VERSION "TE CAN(6) Work x0400000000019499"

NS_ :

BS_:

BU_: BCM CSM DSM_Master DSM_Slave1 Fleet_tracker Tester

BO_ 2364565297 CRNTGEAR: 8 BCM
 SG_ CrntGearEngdSts : 0|2@1+ (1,0) [0|1] "" CSM,DSM_Master,DSM_Slave1

BO_ 2364564771 DBLLCKSNSR: 8 CSM
 SG_ DblLckSnsrRprtdSts : 0|3@1+ (0,0) [0|5] "" BCM

BO_ 2364565809 DBLLCKSNSRTRCK: 8 BCM
 SG_ DblLckSnsrStsTrck : 0|3@1+ (1,0) [0|5] "" DSM_Master

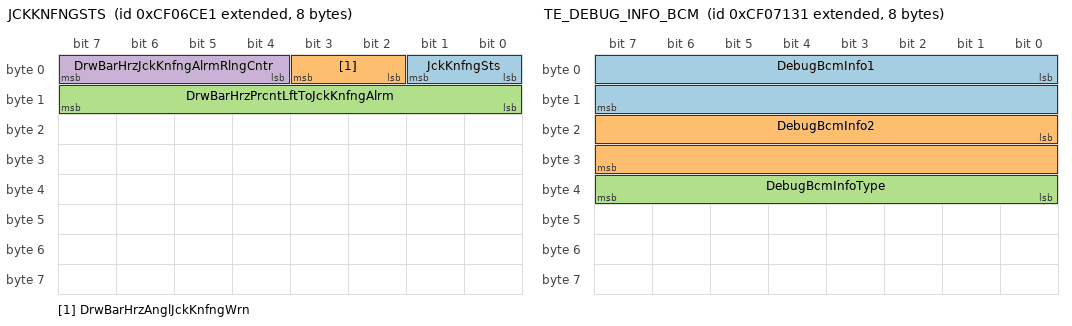
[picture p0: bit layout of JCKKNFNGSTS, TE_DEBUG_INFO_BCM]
BO_ 2364566753 JCKKNFNGSTS: 8 DSM_Master
 SG_ JckKnfngSts : 0|2@1+ (1,0) [0|1] "" BCM
 SG_ DrwBarHrzAnglJckKnfngWrn : 2|2@1+ (1,0) [0|1] "" BCM
 SG_ DrwBarHrzPrcntLftToJckKnfngAlrm : 8|8@1+ (1,0) [0|100] "Percent" BCM
 SG_ DrwBarHrzJckKnfngAlrmRlngCntr : 4|4@1+ (1,0) [0|15] "" BCM

BO_ 2364566321 VEHICLEINFO: 8 BCM
 SG_ KL15Sts : 0|2@1+ (1,0) [0|0] "" CSM,DSM_Master

BO_ 2016 BCMDIAGPHYSRVCREQ: 8 Tester
 SG_ bcmdiagrxsignal : 0|64@1+ (1,0) [0|4] "" BCM

BO_ 2024 BCMDIAGSRVCRSP: 8 BCM

BO_ 2018 DSMMDIAGPHYSRVCREQ: 8 Tester
 SG_ dsmdiagrxsignal : 0|64@1+ (1,0) [0|4] "" DSM_Master,DSM_Slave1

BO_ 2026 DSMMDIAGRVCRSP: 8 DSM_Master

BO_ 2019 DSMSDIAGPHYSRVCREQ: 8 Tester

BO_ 2027 DSMSDIAGSRVCRSP: 8 DSM_Slave1

BO_ 2017 CSMDIAGPHYSRVCREQ: 8 Tester
 SG_ csmdiagrxsignal : 0|64@1+ (1,0) [0|4] "" CSM

BO_ 2025 CSMDIAGSRVCRSP: 8 CSM

BO_ 2047 DIAGFNKSRVCREQ: 8 Tester
 SG_ diagfunctionalsignal : 0|64@1+ (1,0) [0|4] "" BCM,CSM,DSM_Master,DSM_Slave1

BO_ 224 TesterPresentPhys: 8 Tester

BO_ 232 TesterPresentFunc: 8 Tester

BO_ 2364567526 TE_DEBUG_BCM: 8 Tester
 SG_ DebugBcmCmd : 0|8@1+ (1,0) [0|0] "" BCM
 SG_ DebugBcmValue : 16|16@1+ (1,0) [0|0] "" BCM

BO_ 2364567782 TE_DEBUG_CSM: 8 Tester
 SG_ DebugCsmCmd : 0|8@1+ (1,0) [0|0] "" CSM
 SG_ DebugCsmValue : 16|16@1+ (1,0) [0|0] "" CSM

BO_ 2364567857 TE_DEBUG_INFO_BCM: 8 BCM
 SG_ DebugBcmInfo1 : 0|16@1+ (1,0) [0|65535] "" Tester
 SG_ DebugBcmInfo2 : 16|16@1+ (1,0) [0|65535] "" Tester
 SG_ DebugBcmInfoType : 32|8@1+ (1,0) [0|15] "" Tester

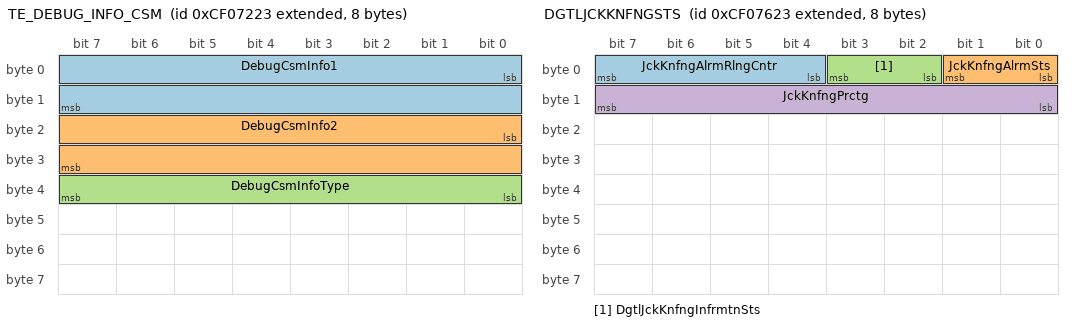
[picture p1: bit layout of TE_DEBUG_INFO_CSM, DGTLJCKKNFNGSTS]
BO_ 2364568099 TE_DEBUG_INFO_CSM: 8 CSM
 SG_ DebugCsmInfo1 : 0|16@1+ (1,0) [0|65535] "" Tester
 SG_ DebugCsmInfo2 : 16|16@1+ (1,0) [0|65535] "" Tester
 SG_ DebugCsmInfoType : 32|8@1+ (1,0) [0|15] "" Tester

BO_ 2364568547 TM_AND_DAT_SETPNT: 8 Fleet_tracker
 SG_ CrntTmAndDateSetPnt : 0|64@1+ (1,0) [0|0] "ms" BCM

BO_ 2364569123 DGTLJCKKNFNGSTS: 8 CSM
 SG_ JckKnfngAlrmRlngCntr : 4|4@1+ (1,0) [0|15] "" BCM
 SG_ JckKnfngAlrmSts : 0|2@1+ (1,0) [0|1] "" BCM
 SG_ DgtlJckKnfngInfrmtnSts : 2|2@1+ (1,0) [0|1] "" BCM
 SG_ JckKnfngPrctg : 8|8@1+ (1,0) [0|100] "Percent" BCM

BO_ 2364568867 CSMSRVCINDREQ: 8 CSM
 SG_ CsmSrvcIndReq : 0|64@1+ (1,0) [0|0] "" BCM

BO_ 2364568801 DSMSRVCINDREQ: 8 DSM_Master
 SG_ DsmSrvcIndReq : 0|64@1+ (1,0) [0|0] "" BCM

BO_ 2364569393 CRNTTMANDDATE: 8 BCM
 SG_ CrntTmAndDate : 0|64@1+ (1,0) [0|1] "ms" CSM,DSM_Master,DSM_Slave1,Fleet_tracker

CM_ "TE CAN";
CM_ BO_ 2364565297 "PGN 61543 Current Gear";
CM_ SG_ 2364565297 CrntGearEngdSts "<Enter a description>";
CM_ BO_ 2364564771 "PGN 61541 Double lock sensor";
CM_ BO_ 2364565809 "PGN 61545 Double lock sensor at truck";
CM_ BO_ 2364566753 "PGN 61548 Jack knifing status";
CM_ SG_ 2364566753 DrwBarHrzJckKnfngAlrmRlngCntr "<Enter a description>";
CM_ BO_ 2364566321 "PGN 61547 Vehicle info";
CM_ BO_ 2016 "BCM diagnostic physical service request";
CM_ SG_ 2016 bcmdiagrxsignal "<Enter a description>";
CM_ BO_ 2024 "BCM Diagnostic physical service response";
CM_ BO_ 2018 "DSM diagnostic physical service request";
CM_ SG_ 2018 dsmdiagrxsignal "<Enter a description>";
CM_ BO_ 2026 "DSM Diagnostic physical service response";
CM_ BO_ 2019 "DSM diagnostic physical service request";
CM_ BO_ 2027 "DSM Diagnostic physical service response";
CM_ BO_ 2017 "CSM diagnostic physical service request";
CM_ SG_ 2017 csmdiagrxsignal "<Enter a description>";
CM_ BO_ 2025 "CSM Diagnose Physical Service Response";
CM_ BO_ 2047 "Diagnostic functional service request";
CM_ SG_ 2047 diagfunctionalsignal "<Enter a description>";
CM_ BO_ 224 "Defines the TesterPresent message for physically addressed requests used to keep a diagnostic session active.";
CM_ BO_ 232 "Defines the TesterPresent message for functionally addressed requests used to keep a diagnostic session active.";
CM_ BO_ 2364567526 "PGN 61551 Debugger request BSM";
CM_ SG_ 2364567526 DebugBcmCmd "<Enter a description>";
CM_ SG_ 2364567526 DebugBcmValue "<Enter a description>";
CM_ BO_ 2364567782 "PGN 61552 Debugger request CSM";
CM_ SG_ 2364567782 DebugCsmCmd "<Enter a description>";
CM_ SG_ 2364567782 DebugCsmValue "<Enter a description>";
CM_ BO_ 2364567857 "PGN 61553 Debugger resoponse BCM";
CM_ SG_ 2364567857 DebugBcmInfo1 "<Enter a description>";
CM_ SG_ 2364567857 DebugBcmInfo2 "<Enter a description>";
CM_ SG_ 2364567857 DebugBcmInfoType "<Enter a description>";
CM_ BO_ 2364568099 "PGN 61554 Debugger resoponse CSM";
CM_ SG_ 2364568099 DebugCsmInfo1 "<Enter a description>";
CM_ SG_ 2364568099 DebugCsmInfo2 "<Enter a description>";
CM_ SG_ 2364568099 DebugCsmInfoType "<Enter a description>";
CM_ BO_ 2364568547 "PGN 61555 Time and date setpoint from GPS. Epoch 1/1 1970";
CM_ SG_ 2364568547 CrntTmAndDateSetPnt "<Enter a description>";
CM_ BO_ 2364569123 "PGN 61555 Digital Jack knifing status";
CM_ SG_ 2364569123 JckKnfngAlrmRlngCntr "<Enter a description>";
CM_ SG_ 2364569123 JckKnfngAlrmSts "<Enter a description>";
CM_ SG_ 2364569123 DgtlJckKnfngInfrmtnSts "<Enter a description>";
CM_ SG_ 2364569123 JckKnfngPrctg "<Enter a description>";
CM_ BO_ 2364568867 "PGN 61557 CSM Service indication request";
CM_ SG_ 2364568867 CsmSrvcIndReq "<Enter a description>";
CM_ BO_ 2364568801 "PGN 61556 DSM service indication request";
CM_ SG_ 2364568801 DsmSrvcIndReq "<Enter a description>";
CM_ BO_ 2364569393 "PGN 61559 Current time and date";
CM_ SG_ 2364569393 CrntTmAndDate "<Enter a description>";

BA_DEF_  "DatabaseVersion" STRING ;
BA_DEF_  "ProtocolType" STRING ;
BA_DEF_  "SAE_J1939_21_SpecVersion" STRING ;
BA_DEF_  "SAE_J1939_71_SpecVersion" STRING ;
BA_DEF_  "SAE_J1939_73_SpecVersion" STRING ;
BA_DEF_  "Manufacturer" STRING ;
BA_DEF_  "BusType" STRING ;
BA_DEF_ BU_  "ECU" STRING ;
BA_DEF_ BU_  "NmJ1939AAC" INT 0 1;
BA_DEF_ BU_  "NmJ1939IndustryGroup" INT 0 7;
BA_DEF_ BU_  "NmJ1939System" INT 0 127;
BA_DEF_ BU_  "NmJ1939SystemInstance" INT 0 15;
BA_DEF_ BU_  "NmJ1939ECUInstance" INT 0 3;
BA_DEF_ BU_  "NmJ1939Function" INT 0 255;
BA_DEF_ BU_  "NmJ1939FunctionInstance" INT 0 7;
BA_DEF_ BU_  "NmJ1939ManufacturerCode" INT 0 2047;
BA_DEF_ BU_  "NmJ1939IdentityNumber" INT 0 2097151;
BA_DEF_ BU_  "NmStationAddress" INT 0 255;
BA_DEF_ BU_  "NodeLayerModules" STRING ;
BA_DEF_ BO_  "SingleFrame" INT 0 1;
BA_DEF_ BO_  "GenMsgStartDelayTime" INT 0 10000;
BA_DEF_ BO_  "GenMsgDelayTime" INT 0 10000;
BA_DEF_ BO_  "GenMsgILSupport" ENUM  "Yes","No";
BA_DEF_ BO_  "SAE_Document" STRING ;
BA_DEF_ BO_  "GenMsgRequestable" INT 0 1;
BA_DEF_ BO_  "GenMsgSendType" ENUM  "cyclic","spontan","cyclicIfActive","spontanWithDelay","cyclicAndSpontan","cyclicAndSpontanWithDelay","spontanWithRepitition","cyclicIfActiveAndSpontanWD","noMsgSendType";
BA_DEF_ BO_  "VFrameFormat" ENUM  "StandardCAN","ExtendedCAN","reserved","J1939PG";
BA_DEF_ BO_  "GenMsgCycleTime" INT 0 3600000;
BA_DEF_ BO_  "GenMsgNrOfRepetition" INT 0 1000;
BA_DEF_ SG_  "SignalStartPosition" INT 0 63;
BA_DEF_ SG_  "GenSigStartValue" FLOAT 0 10000;
BA_DEF_ SG_  "GenSigSendType" ENUM  "Cyclic","OnWrite","OnWriteWithRepetition","OnChange","OnChangeWithRepetition","IfActive","IfActiveWithRepetition","NoSigSendType";
BA_DEF_ SG_  "GenSigILSupport" ENUM  "Yes","No";
BA_DEF_ SG_  "SPN" INT 0 524287;
BA_DEF_ SG_  "SigType" ENUM  "Default","Range","RangeSigned","ASCII","Discrete","Control","ReferencePGN","DTC","StringDelimiter","StringLength","StringLengthControl";

BA_DEF_DEF_  "DatabaseVersion" "";
BA_DEF_DEF_  "ProtocolType" "-";
BA_DEF_DEF_  "SAE_J1939_21_SpecVersion" "";
BA_DEF_DEF_  "SAE_J1939_71_SpecVersion" "";
BA_DEF_DEF_  "SAE_J1939_73_SpecVersion" "";
BA_DEF_DEF_  "Manufacturer" "VBG Truck Equipment";
BA_DEF_DEF_  "BusType" "CAN";
BA_DEF_DEF_  "ECU" "";
BA_DEF_DEF_  "NmJ1939AAC" 0;
BA_DEF_DEF_  "NmJ1939IndustryGroup" 1;
BA_DEF_DEF_  "NmJ1939System" 0;
BA_DEF_DEF_  "NmJ1939SystemInstance" 0;
BA_DEF_DEF_  "NmJ1939ECUInstance" 0;
BA_DEF_DEF_  "NmJ1939Function" 0;
BA_DEF_DEF_  "NmJ1939FunctionInstance" 0;
BA_DEF_DEF_  "NmJ1939ManufacturerCode" 0;
BA_DEF_DEF_  "NmJ1939IdentityNumber" 0;
BA_DEF_DEF_  "NmStationAddress" 0;
BA_DEF_DEF_  "NodeLayerModules" "CANoeILNLVector.dll";
BA_DEF_DEF_  "SingleFrame" 1;
BA_DEF_DEF_  "GenMsgStartDelayTime" 0;
BA_DEF_DEF_  "GenMsgDelayTime" 0;
BA_DEF_DEF_  "GenMsgILSupport" "Yes";
BA_DEF_DEF_  "SAE_Document" "";
BA_DEF_DEF_  "GenMsgRequestable" ;
BA_DEF_DEF_  "GenMsgSendType" "NoMsgSendType";
BA_DEF_DEF_  "VFrameFormat" "J1939PG";
BA_DEF_DEF_  "GenMsgCycleTime" ;
BA_DEF_DEF_  "GenMsgNrOfRepetition" 1;
BA_DEF_DEF_  "SignalStartPosition" 0;
BA_DEF_DEF_  "GenSigStartValue" 0;
BA_DEF_DEF_  "GenSigSendType" "NoSigSendType";
BA_DEF_DEF_  "GenSigILSupport" "Yes";
BA_DEF_DEF_  "SPN" 0;
BA_DEF_DEF_  "SigType" "-";
BA_ "ProtocolType" "J1939";
BA_ "DatabaseVersion" "1.0";
BA_ "SAE_J1939_21_SpecVersion" "201603";
BA_ "SAE_J1939_71_SpecVersion" "201610";
BA_ "SAE_J1939_73_SpecVersion" "201705";
BA_ "ECU" BU_ BCM "BCM";
BA_ "NmJ1939Function" BU_ BCM 255;
BA_ "NmJ1939ManufacturerCode" BU_ BCM 925;
BA_ "NmJ1939IdentityNumber" BU_ BCM 1048575;
BA_ "NmStationAddress" BU_ BCM 49;
BA_ "ECU" BU_ CSM "CSM";
BA_ "NmJ1939Function" BU_ CSM 255;
BA_ "NmJ1939ManufacturerCode" BU_ CSM 926;
BA_ "NmJ1939IdentityNumber" BU_ CSM 1048574;
BA_ "NmStationAddress" BU_ CSM 35;
BA_ "ECU" BU_ DSM_Master "DSM";
BA_ "NmJ1939Function" BU_ DSM_Master 255;
BA_ "NmJ1939ManufacturerCode" BU_ DSM_Master 926;
BA_ "NmJ1939IdentityNumber" BU_ DSM_Master 1048573;
BA_ "NmStationAddress" BU_ DSM_Master 225;
BA_ "NmStationAddress" BU_ DSM_Slave1 226;
BA_ "ECU" BU_ DSM_Slave1 "DSM";
BA_ "NmJ1939Function" BU_ DSM_Slave1 255;
BA_ "NmJ1939IdentityNumber" BU_ DSM_Slave1 1048573;
BA_ "NmJ1939ManufacturerCode" BU_ DSM_Slave1 926;
BA_ "ECU" BU_ Fleet_tracker "IOT";
BA_ "NmJ1939Function" BU_ Fleet_tracker 255;
BA_ "NmJ1939ManufacturerCode" BU_ Fleet_tracker 927;
BA_ "NmJ1939IdentityNumber" BU_ Fleet_tracker 1048572;
BA_ "NmStationAddress" BU_ Fleet_tracker 227;
BA_ "ECU" BU_ Tester "Service tool";
BA_ "NmStationAddress" BU_ Tester 230;
BA_ "NmJ1939Function" BU_ Tester 255;
BA_ "NmJ1939IdentityNumber" BU_ Tester 1048576;
BA_ "NmJ1939ManufacturerCode" BU_ Tester 930;
BA_ "SingleFrame" BO_ 2364565297 0;
BA_ "GenMsgCycleTime" BO_ 2364565297 100;
BA_ "GenMsgSendType" BO_ 2364565297 0;
BA_ "SAE_Document" BO_ 2364565297 "??";
BA_ "GenMsgRequestable" BO_ 2364565297 0;
BA_ "SingleFrame" BO_ 2364564771 0;
BA_ "GenMsgCycleTime" BO_ 2364564771 100;
BA_ "GenMsgSendType" BO_ 2364564771 0;
BA_ "GenSigSendType" SG_ 2364564771 DblLckSnsrRprtdSts 0;
BA_ "SingleFrame" BO_ 2364565809 0;
BA_ "GenMsgCycleTime" BO_ 2364565809 100;
BA_ "GenMsgSendType" BO_ 2364565809 0;
BA_ "GenSigSendType" SG_ 2364565809 DblLckSnsrStsTrck 0;
BA_ "SingleFrame" BO_ 2364566753 0;
BA_ "GenMsgCycleTime" BO_ 2364566753 100;
BA_ "GenMsgSendType" BO_ 2364566753 0;
BA_ "GenSigSendType" SG_ 2364566753 JckKnfngSts 0;
BA_ "GenSigSendType" SG_ 2364566753 DrwBarHrzAnglJckKnfngWrn 0;
BA_ "GenSigSendType" SG_ 2364566753 DrwBarHrzPrcntLftToJckKnfngAlrm 0;
BA_ "GenSigSendType" SG_ 2364566753 DrwBarHrzJckKnfngAlrmRlngCntr 0;
BA_ "SingleFrame" BO_ 2364566321 0;
BA_ "GenMsgCycleTime" BO_ 2364566321 100;
BA_ "GenMsgSendType" BO_ 2364566321 0;
BA_ "GenSigSendType" SG_ 2364566321 KL15Sts 0;
BA_ "SingleFrame" BO_ 2016 0;
BA_ "VFrameFormat" BO_ 2016 0;
BA_ "GenMsgSendType" BO_ 2016 8;
BA_ "SingleFrame" BO_ 2024 0;
BA_ "VFrameFormat" BO_ 2024 0;
BA_ "GenMsgSendType" BO_ 2024 8;
BA_ "SingleFrame" BO_ 2018 0;
BA_ "VFrameFormat" BO_ 2018 0;
BA_ "GenMsgSendType" BO_ 2018 8;
BA_ "SingleFrame" BO_ 2026 0;
BA_ "VFrameFormat" BO_ 2026 0;
BA_ "GenMsgSendType" BO_ 2026 8;
BA_ "SingleFrame" BO_ 2019 0;
BA_ "VFrameFormat" BO_ 2019 0;
BA_ "GenMsgSendType" BO_ 2019 8;
BA_ "SingleFrame" BO_ 2027 0;
BA_ "VFrameFormat" BO_ 2027 0;
BA_ "GenMsgSendType" BO_ 2027 8;
BA_ "SingleFrame" BO_ 2017 0;
BA_ "VFrameFormat" BO_ 2017 0;
BA_ "GenMsgSendType" BO_ 2017 8;
BA_ "SingleFrame" BO_ 2025 0;
BA_ "VFrameFormat" BO_ 2025 0;
BA_ "GenMsgSendType" BO_ 2025 8;
BA_ "SingleFrame" BO_ 2047 0;
BA_ "VFrameFormat" BO_ 2047 0;
BA_ "GenMsgSendType" BO_ 2047 8;
BA_ "SingleFrame" BO_ 224 0;
BA_ "VFrameFormat" BO_ 224 0;
BA_ "GenMsgSendType" BO_ 224 8;
BA_ "SingleFrame" BO_ 232 0;
BA_ "VFrameFormat" BO_ 232 0;
BA_ "GenMsgSendType" BO_ 232 8;
BA_ "SingleFrame" BO_ 2364567526 0;
BA_ "GenMsgSendType" BO_ 2364567526 8;
BA_ "SingleFrame" BO_ 2364567782 0;
BA_ "GenMsgSendType" BO_ 2364567782 8;
BA_ "SingleFrame" BO_ 2364567857 0;
BA_ "GenMsgSendType" BO_ 2364567857 8;
BA_ "SingleFrame" BO_ 2364568099 0;
BA_ "GenMsgSendType" BO_ 2364568099 8;
BA_ "SingleFrame" BO_ 2364568547 0;
BA_ "GenMsgSendType" BO_ 2364568547 0;
BA_ "GenMsgCycleTime" BO_ 2364568547 1000;
BA_ "GenSigSendType" SG_ 2364568547 CrntTmAndDateSetPnt 0;
BA_ "SingleFrame" BO_ 2364569123 0;
BA_ "GenMsgSendType" BO_ 2364569123 0;
BA_ "GenMsgCycleTime" BO_ 2364569123 100;
BA_ "GenSigSendType" SG_ 2364569123 JckKnfngAlrmRlngCntr 0;
BA_ "GenSigSendType" SG_ 2364569123 JckKnfngAlrmSts 0;
BA_ "GenSigSendType" SG_ 2364569123 DgtlJckKnfngInfrmtnSts 0;
BA_ "GenSigSendType" SG_ 2364569123 JckKnfngPrctg 0;
BA_ "SingleFrame" BO_ 2364568867 0;
BA_ "GenMsgSendType" BO_ 2364568867 0;
BA_ "GenMsgCycleTime" BO_ 2364568867 1000;
BA_ "GenSigSendType" SG_ 2364568867 CsmSrvcIndReq 0;
BA_ "SingleFrame" BO_ 2364568801 0;
BA_ "GenMsgSendType" BO_ 2364568801 0;
BA_ "GenMsgCycleTime" BO_ 2364568801 1000;
BA_ "GenSigSendType" SG_ 2364568801 DsmSrvcIndReq 0;
BA_ "SingleFrame" BO_ 2364569393 0;
BA_ "GenMsgSendType" BO_ 2364569393 0;
BA_ "GenMsgCycleTime" BO_ 2364569393 1000;
VAL_ 2364565297 CrntGearEngdSts 0 "Not Active" 1 "Active" ;
VAL_ 2364564771 DblLckSnsrRprtdSts 0 "Unlocked" 1 "Locked" 2 "Not present" 3 "Undefined" 4 "Inhibited" ;
VAL_ 2364565809 DblLckSnsrStsTrck 0 "Unlocked" 1 "Locked" 2 "Not present" 3 "Undefined" 4 "Inhibited" ;
VAL_ 2364566753 JckKnfngSts 0 "Not Active" 1 "Active" ;
VAL_ 2364566753 DrwBarHrzAnglJckKnfngWrn 0 "Not Active" 1 "Active" ;
VAL_ 2364566321 KL15Sts 0 "Not Active" 1 "Active" ;
VAL_ 2364569123 JckKnfngAlrmSts 0 "Not Active" 1 "Active" ;
VAL_ 2364569123 DgtlJckKnfngInfrmtnSts 0 "Not Active" 1 "Active" ;
